# ATSAMA5D28CLD2G register map
Vendor: Microchip Technology; Series: SAMA5D2; File version: 0
Registers are 32-bit, read-write, reset 0x0 unless marked. A register's access mark holds for its fields unless they carry their own. Offsets are from the block's base; [hi:lo] are bit positions; lines under a group give offsets from that group; {n}, {i} and the like mark numbered series; 'fields as' and 'values as' point back to an identical list.

## RTC — Real-time Clock
Base 0xF80480B0; register names take the prefix RTC_
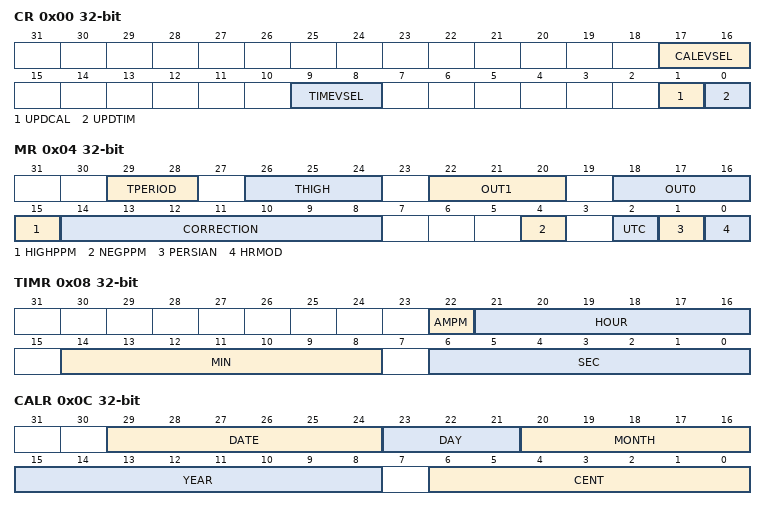
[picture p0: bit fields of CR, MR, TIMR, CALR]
0x00 CR — Control Register
  [17:16] CALEVSEL — Calendar Event Selection
    0=WEEK (Week change (every Monday at time 00:00:00)); 1=MONTH (Month change (every 01 of each month at time 00:00:00)); 2=YEAR (Year change (every January 1 at time 00:00:00))
  [9:8] TIMEVSEL — Time Event Selection
    0=MINUTE (Minute change); 1=HOUR (Hour change); 2=MIDNIGHT (Every day at midnight); 3=NOON (Every day at noon)
  [1] UPDCAL — Update Request Calendar Register
  [0] UPDTIM — Update Request Time Register
0x04 MR — Mode Register
  [29:28] TPERIOD — Period of the Output Pulse
    0=P_1S (1 second); 1=P_500MS (500 ms); 2=P_250MS (250 ms); 3=P_125MS (125 ms)
  [26:24] THIGH — High Duration of the Output Pulse
    0=H_31MS (31.2 ms); 1=H_16MS (15.6 ms); 2=H_4MS (3.91 ms); 3=H_976US (976 us); 4=H_488US (488 us); 5=H_122US (122 us); 6=H_30US (30.5 us); 7=H_15US (15.2 us)
  [22:20] OUT1 — ADC Last Channel Trigger Event Source Selection
    0=NO_WAVE (No waveform, stuck at '0'); 1=FREQ1HZ (1 Hz square wave); 2=FREQ32HZ (32 Hz square wave); 3=FREQ64HZ (64 Hz square wave); 4=FREQ512HZ (512 Hz square wave); 5=ALARM_TOGGLE (Output toggles when alarm flag rises); 6=ALARM_FLAG (Output is a copy of the alarm flag); 7=PROG_PULSE (Duty cycle programmable pulse)
  [18:16] OUT0 — All ADC Channel Trigger Event Source Selection
    values as OUT1
  [15] HIGHPPM — HIGH PPM Correction
  [14:8] CORRECTION — Slow Clock Correction
  [4] NEGPPM — NEGative PPM Correction
  [2] UTC — UTC Time Format
  [1] PERSIAN — PERSIAN Calendar
  [0] HRMOD — 12-/24-hour Mode
0x08 TIMR — Time Register
  [22] AMPM — Ante Meridiem Post Meridiem Indicator
  [21:16] HOUR — Current Hour
  [14:8] MIN — Current Minute
  [6:0] SEC — Current Second
0x08 TIMR_UTC_MODE_MODE (alternate view of TIMR) — Time Register
  [31:0] UTC_TIME — Current UTC Time
0x0C CALR — Calendar Register
  [29:24] DATE — Current Day in Current Month
  [23:21] DAY — Current Day in Current Week
  [20:16] MONTH — Current Month
  [15:8] YEAR — Current Year
  [6:0] CENT — Current Century
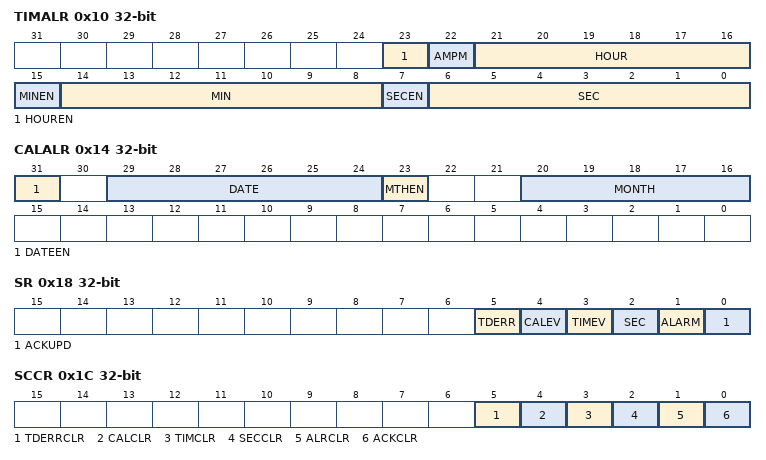
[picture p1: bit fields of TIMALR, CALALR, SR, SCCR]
0x10 TIMALR — Time Alarm Register
  [23] HOUREN — Hour Alarm Enable
  [22] AMPM — AM/PM Indicator
  [21:16] HOUR — Hour Alarm
  [15] MINEN — Minute Alarm Enable
  [14:8] MIN — Minute Alarm
  [7] SECEN — Second Alarm Enable
  [6:0] SEC — Second Alarm
0x10 TIMALR_UTC_MODE_MODE (alternate view of TIMALR) — Time Alarm Register
  [31:0] UTC_TIME — UTC_TIME Alarm
0x14 CALALR — Calendar Alarm Register
  [31] DATEEN — Date Alarm Enable
  [29:24] DATE — Date Alarm
  [23] MTHEN — Month Alarm Enable
  [20:16] MONTH — Month Alarm
0x14 CALALR_UTC_MODE_MODE (alternate view of CALALR) — Calendar Alarm Register
  [0] UTCEN — UTC Alarm Enable
0x18 SR ro — Status Register
  [5] TDERR — Time and/or Date Free Running Error
    0=CORRECT (The internal free running counters are carrying valid values since the last read of the Status Register (RTC_SR).); 1=ERR_TIMEDATE (The internal free running counters have been corrupted (invalid date or time, non-BCD values) since the last read and/or they are still invalid.)
  [4] CALEV — Calendar Event
    0=NO_CALEVENT (No calendar event has occurred since the last clear.); 1=CALEVENT (At least one calendar event has occurred since the last clear.)
  [3] TIMEV — Time Event
    0=NO_TIMEVENT (No time event has occurred since the last clear.); 1=TIMEVENT (At least one time event has occurred since the last clear.)
  [2] SEC — Second Event
    0=NO_SECEVENT (No second event has occurred since the last clear.); 1=SECEVENT (At least one second event has occurred since the last clear.)
  [1] ALARM — Alarm Flag
    0=NO_ALARMEVENT (No alarm matching condition occurred.); 1=ALARMEVENT (An alarm matching condition has occurred.)
  [0] ACKUPD — Acknowledge for Update
    0=FREERUN (Time and calendar registers cannot be updated.); 1=UPDATE (Time and calendar registers can be updated.)
0x1C SCCR wo — Status Clear Command Register
  [5] TDERRCLR — Time and/or Date Free Running Error Clear
  [4] CALCLR — Calendar Clear
  [3] TIMCLR — Time Clear
  [2] SECCLR — Second Clear
  [1] ALRCLR — Alarm Clear
  [0] ACKCLR — Acknowledge Clear
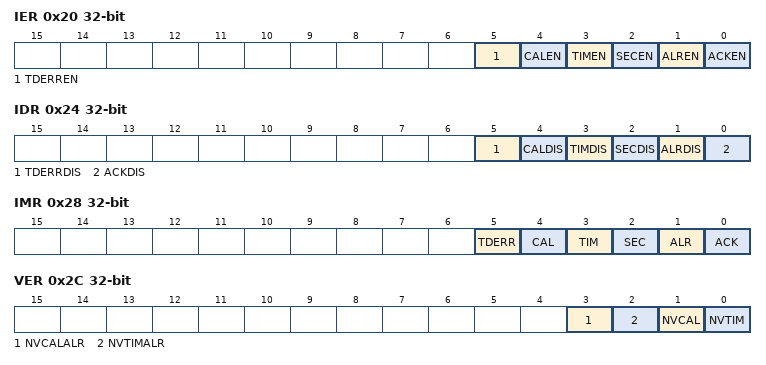
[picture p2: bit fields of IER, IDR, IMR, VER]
0x20 IER wo — Interrupt Enable Register
  [5] TDERREN — Time and/or Date Error Interrupt Enable
  [4] CALEN — Calendar Event Interrupt Enable
  [3] TIMEN — Time Event Interrupt Enable
  [2] SECEN — Second Event Interrupt Enable
  [1] ALREN — Alarm Interrupt Enable
  [0] ACKEN — Acknowledge Update Interrupt Enable
0x24 IDR wo — Interrupt Disable Register
  [5] TDERRDIS — Time and/or Date Error Interrupt Disable
  [4] CALDIS — Calendar Event Interrupt Disable
  [3] TIMDIS — Time Event Interrupt Disable
  [2] SECDIS — Second Event Interrupt Disable
  [1] ALRDIS — Alarm Interrupt Disable
  [0] ACKDIS — Acknowledge Update Interrupt Disable
0x28 IMR ro — Interrupt Mask Register
  [5] TDERR — Time and/or Date Error Mask
  [4] CAL — Calendar Event Interrupt Mask
  [3] TIM — Time Event Interrupt Mask
  [2] SEC — Second Event Interrupt Mask
  [1] ALR — Alarm Interrupt Mask
  [0] ACK — Acknowledge Update Interrupt Mask
0x2C VER ro — Valid Entry Register
  [3] NVCALALR — Non-valid Calendar Alarm
  [2] NVTIMALR — Non-valid Time Alarm
  [1] NVCAL — Non-valid Calendar
  [0] NVTIM — Non-valid Time
{0xB0+0xC*i} RTC_TS[{i}] (i=0..1) group
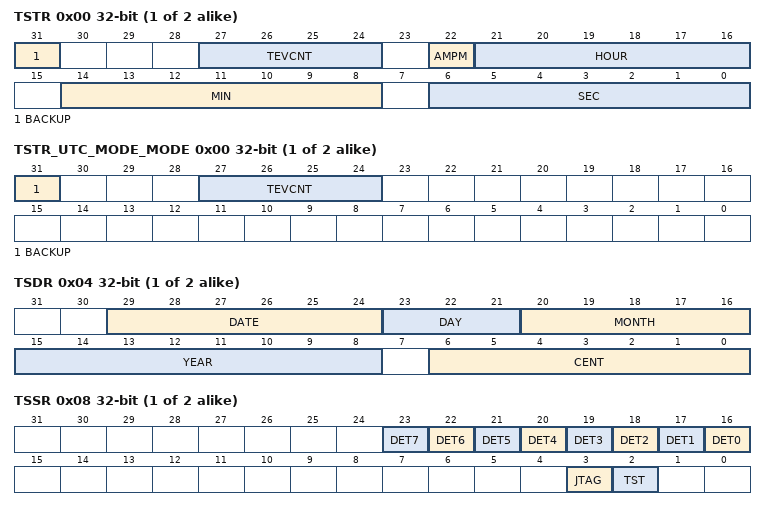
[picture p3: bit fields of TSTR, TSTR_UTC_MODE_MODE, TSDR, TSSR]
  0x00 TSTR ro — TimeStamp Time Register 0
    [31] BACKUP — System Mode of the Tamper
    [27:24] TEVCNT — Tamper Events Counter
    [22] AMPM — AM/PM Indicator of the Tamper
    [21:16] HOUR — Hours of the Tamper
    [14:8] MIN — Minutes of the Tamper
    [6:0] SEC — Seconds of the Tamper
  0x00 TSTR_UTC_MODE_MODE ro (alternate view of TSTR) — TimeStamp Time Register 0
    [31] BACKUP — System Mode of the Tamper (cleared by reading RTC_TSSR0)
    [27:24] TEVCNT — Tamper Events Counter (cleared by reading RTC_TSSR0)
  0x04 TSDR ro — TimeStamp Date Register 0
    [29:24] DATE — Date of the Tamper
    [23:21] DAY — Day of the Tamper
    [20:16] MONTH — Month of the Tamper
    [15:8] YEAR — Year of the Tamper
    [6:0] CENT — Century of the Tamper
  0x04 TSDR_UTC_MODE_MODE ro (alternate view of TSDR) — TimeStamp Date Register 0
    [31:0] UTC_TIME — Time of the Tamper (UTC format)
  0x08 TSSR ro — TimeStamp Source Register 0
    [n+16] DET{n} (n=0..7) — PIOBU Intrusion Detector
    [3] JTAG — JTAG Pins Monitor
    [2] TST — Test Pin Monitor

## Notices in the file
Copyright (c) 2022 Microchip Technology Inc.
SPDX-License-Identifier: Apache-2.0
Licensed under the Apache License, Version 2.0 (the "License");
you may not use this file except in compliance with the License.
You may obtain a copy of the License at
http://www.apache.org/licenses/LICENSE-2.0
Unless required by applicable law or agreed to in writing, software
distributed under the License is distributed on an "AS IS" BASIS,
WITHOUT WARRANTIES OR CONDITIONS OF ANY KIND, either express or implied.
See the License for the specific language governing permissions and
limitations under the License.
